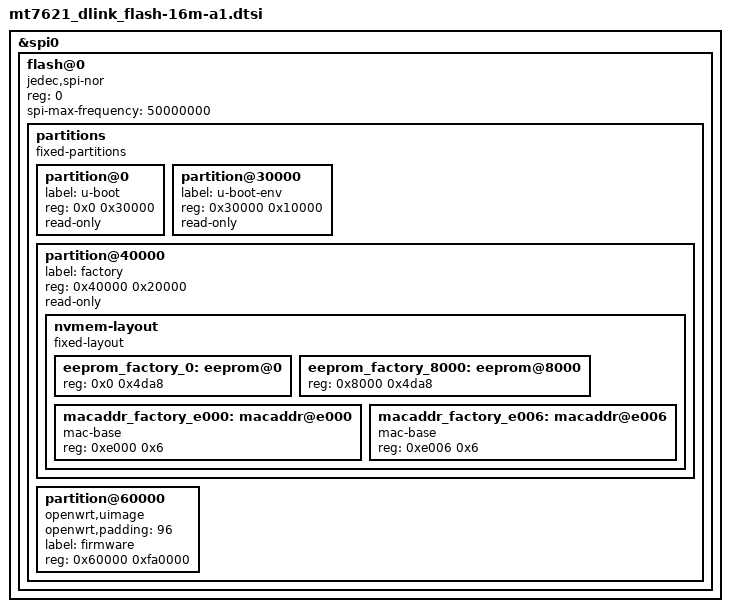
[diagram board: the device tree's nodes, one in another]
// SPDX-License-Identifier: GPL-2.0-or-later OR MIT

&spi0 {
	status = "okay";

	flash@0 {
		compatible = "jedec,spi-nor";
		reg = <0>;
		spi-max-frequency = <50000000>;

		partitions {
			compatible = "fixed-partitions";
			#address-cells = <1>;
			#size-cells = <1>;

			partition@0 {
				label = "u-boot";
				reg = <0x0 0x30000>;
				read-only;
			};

			partition@30000 {
				label = "u-boot-env";
				reg = <0x30000 0x10000>;
				read-only;
			};

			partition@40000 {
				label = "factory";
				reg = <0x40000 0x20000>;
				read-only;

				nvmem-layout {
					compatible = "fixed-layout";
					#address-cells = <1>;
					#size-cells = <1>;

					eeprom_factory_0: eeprom@0 {
						reg = <0x0 0x4da8>;
					};

					eeprom_factory_8000: eeprom@8000 {
						reg = <0x8000 0x4da8>;
					};

					macaddr_factory_e000: macaddr@e000 {
						compatible = "mac-base";
						reg = <0xe000 0x6>;
						#nvmem-cell-cells = <1>;
					};

					macaddr_factory_e006: macaddr@e006 {
						compatible = "mac-base";
						reg = <0xe006 0x6>;
						#nvmem-cell-cells = <1>;
					};
				};
			};

			partition@60000 {
				compatible = "openwrt,uimage", "denx,uimage";
				openwrt,padding = <96>;
				label = "firmware";
				reg = <0x60000 0xfa0000>;
			};
		};
	};
};
